VERSION ""

NS_ :

BS_:

BU_: node02 node01

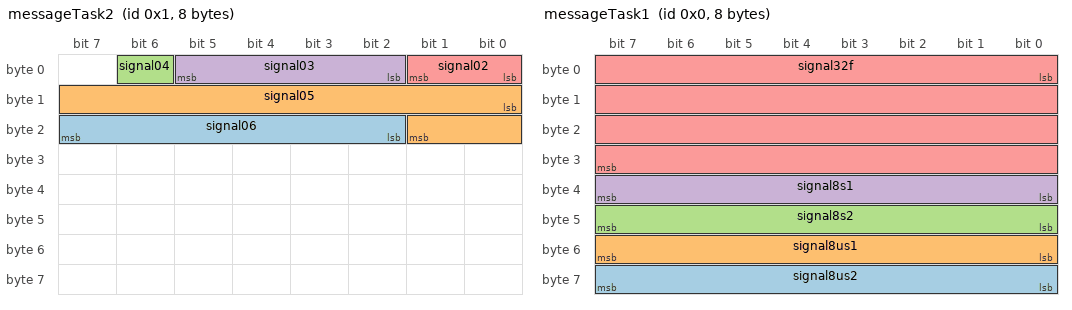
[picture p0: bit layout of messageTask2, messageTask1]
BO_ 1 messageTask2: 8 node01
 SG_ signal06 : 18|6@1+ (1,0) [0|0] ""  node02
 SG_ signal05 : 8|10@1- (1,0) [0|0] ""  node02
 SG_ signal04 : 6|1@1+ (1,0) [0|0] ""  node02
 SG_ signal03 : 2|4@1+ (1,0) [0|0] ""  node02
 SG_ signal02 : 0|2@1- (1,0) [0|0] ""  node02

BO_ 0 messageTask1: 8 node01
 SG_ signal8us2 : 56|8@1+ (1,0) [0|0] "" Vector__XXX
 SG_ signal8us1 : 48|8@1+ (1,0) [0|0] "" Vector__XXX
 SG_ signal8s2 : 40|8@1- (1,0) [0|0] "" Vector__XXX
 SG_ signal8s1 : 32|8@1- (0.25,0) [0|63.5] "Nm" Vector__XXX
 SG_ signal32f : 0|32@1- (1,0) [0|0] ""  node02

BO_ 256 message01: 8 node01
 SG_ signal01 : 0|8@1- (1,0) [0|0] ""  node02

BA_DEF_  "BusType" STRING ;
BA_DEF_DEF_  "BusType" "CAN";
SIG_VALTYPE_ 0 signal32f : 1;
